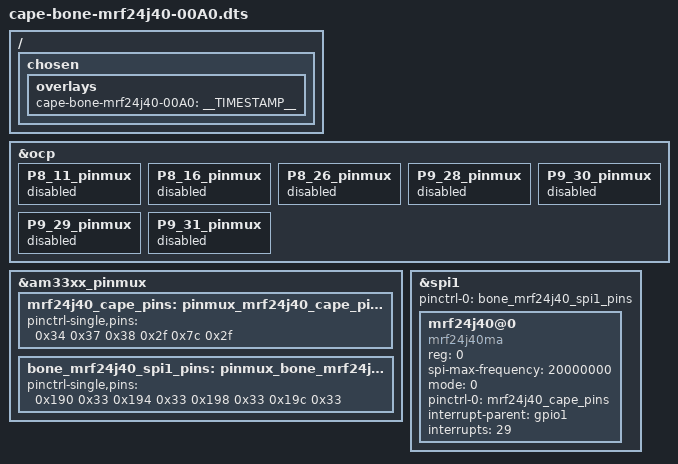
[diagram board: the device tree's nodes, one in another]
/*
 * Copyright (C) 2013 Alan Ott <alan@signal11.us>
 *
 * This program is free software; you can redistribute it and/or modify
 * it under the terms of the GNU General Public License version 2 as
 * published by the Free Software Foundation.
 */

/dts-v1/;
/plugin/;

#include <dt-bindings/board/am335x-bbw-bbb-base.h>
#include <dt-bindings/pinctrl/am33xx.h>

/ {
	/*
	 * Helper to show loaded overlays under: /proc/device-tree/chosen/overlays/
	 */
	fragment@0 {
		target-path="/";
		__overlay__ {

			chosen {
				overlays {
					cape-bone-mrf24j40-00A0 = __TIMESTAMP__;
				};
			};
		};
	};

	/*
	 * Free up the pins used by the cape from the pinmux helpers.
	 */
	fragment@1 {
		target = <&ocp>;
		__overlay__ {
			P8_11_pinmux { status = "disabled"; };
			P8_16_pinmux { status = "disabled"; };
			P8_26_pinmux { status = "disabled"; };

			P9_28_pinmux { status = "disabled"; };	/* spi1_cs0 */
			P9_30_pinmux { status = "disabled"; };	/* spi1_d1 */
			P9_29_pinmux { status = "disabled"; };	/* spi1_d0 */
			P9_31_pinmux { status = "disabled"; };	/* spi1_sclk */
		};
	};

	fragment@2 {
		target = <&am33xx_pinmux>;
		__overlay__ {
			mrf24j40_cape_pins: pinmux_mrf24j40_cape_pins {
				pinctrl-single,pins = <
					/* Pinmux comes from TRM section
					   9.3.1: CONTROL_MODULE Regusters. */

					/* so use GPIO1_13 (rst), GPIO1_14 (wake), then SPI1_CS0 (CS), and GPIO1_29 (INT) */
					0x34 0x37 /* gpmc_ad13.gpio1_13 input, pull up, mode 7 */
					0x38 0x2f /* gpmc_ad14.gpio1_14 input, no pull, mode 7 */
					0x7c 0x2f /* gpmc_csn0.gpio1_29 input, no pull, mode 7 */
				>;
			};

			bone_mrf24j40_spi1_pins: pinmux_bone_mrf24j40_spi1_pins {
				pinctrl-single,pins = <
					0x190 0x33	/* mcasp0_aclkx.spi1_sclk, RX_ENABLED | PULLUP | MODE3 */
					0x194 0x33	/* mcasp0_fsx.spi1_d0, RX_ENABLED | PULLUP | MODE3 */
					0x198 0x33	/* mcasp0_axr0.spi1_d1, RX_ENABLED | PULLUP | MODE3 */
					0x19c 0x33	/* mcasp0_ahclkr.spi1_cs0, RX_ENABLED | PULLUP | MODE3 */
				>;
			};
		};
	};

	fragment@3 {
		target = <&spi1>;
		__overlay__ {
			#address-cells = <1>;
			#size-cells = <0>;

			status = "okay";
			pinctrl-names = "default";
			pinctrl-0 = <&bone_mrf24j40_spi1_pins>;

			mrf24j40@0 {
				compatible = "mrf24j40ma";
				reg = <0>; /* CHIPSEL */
				spi-max-frequency = <20000000>;
				mode = <0>;
				pinctrl-names = "default";
				pinctrl-0 = <&mrf24j40_cape_pins>;

				interrupt-parent = <&gpio1>;
				interrupts = <29>;

				//mrf24j40-wake = <&gpio4 19>;
				//mrf24j40-reset = <gpio21 0>;
			};
		};
	};
};
